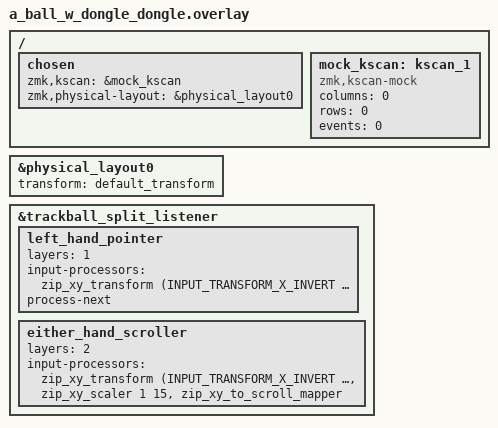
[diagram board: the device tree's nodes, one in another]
 // Can't have the kscan0 here, that one's physical
/* 
    Central side is the only one that is aware of .keymap,
    so put all input processors you want to take effect in input listener here.
*/

#include "cosmos.dtsi"
#include "split_input.dtsi"
#include "cosmos-layouts.dtsi"
#include <input/processors.dtsi>
#include <dt-bindings/zmk/input_transform.h>

&physical_layout0 {
    transform = <&default_transform>;
};

/* More about input processors: https://zmk.dev/docs/keymaps/input-processors#input-processors-overview */

&trackball_split_listener { // local trackball input split device child node, receiving events from the peripheral and raising them locally
	status = "okay";

    /* base processor chain on all layers */
    /* input-processors = <&zip_xy_scaler 5 5>; */

    /* layer-0 right left hand pointer */
    /* This default layer should not have any additional transformations. 
       All other layers will add to it, and then have all those extra steps removed
       when returned to the base layer.
    */

    /* layer-1 left hand pointer */
    left_hand_pointer: left_hand_pointer {
        layers           = <1>;
        input-processors = <
            &zip_xy_transform (INPUT_TRANSFORM_X_INVERT | INPUT_TRANSFORM_Y_INVERT) // Inverts the pointer direction
	   // The regular scrolling assumes the scroling wheel, which is not used here, so &zip_scroll_transform is not applicable and does not work.
	   // &zip_scroll_transform (INPUT_TRANSFORM_X_INVERT | INPUT_TRANSFORM_Y_INVERT) // Inverts the pointer direction, from the default inversion..
        >;
	process-next; // To process the scroller layer, if/when it is activated. Without this command the processing would stop here.
    };

    /* layer-2 both hand scroll override */
    either_hand_scroller: either_hand_scroller {
        layers           = <2>;
        input-processors = <
            &zip_xy_transform (INPUT_TRANSFORM_X_INVERT | INPUT_TRANSFORM_Y_INVERT) // Inverts the pointer direction.
            &zip_xy_scaler 1 15                              // Scales the scroll speed
            &zip_xy_to_scroll_mapper                         // Converts XY movement to scroll events
        >;
    };
};

/ {
    chosen {
        zmk,kscan = &mock_kscan;
        zmk,physical-layout = &physical_layout0;
    };

    mock_kscan: kscan_1 {
        compatible = "zmk,kscan-mock";
        columns = <0>;
        rows = <0>;
        events = <0>;
    };
};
